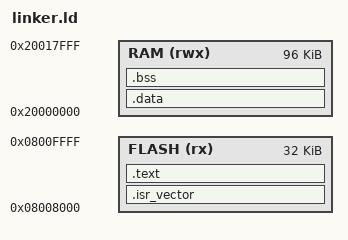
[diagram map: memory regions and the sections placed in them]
ENTRY(Reset_Handler)

MEMORY
{
    FLASH (rx) : ORIGIN = 0x08008000, LENGTH = 32K
    RAM (rwx)  : ORIGIN = 0x20000000, LENGTH = 96K
}

_estack = ORIGIN(RAM) + LENGTH(RAM);

SECTIONS
{
    .isr_vector :
    {
        . = ALIGN(128);
        KEEP(*(.isr_vector))
    } > FLASH

    .text :
    {
        *(.text*)
        *(.rodata*)
        . = ALIGN(4);
        _etext = .;
    } > FLASH

    .data : AT(_etext)
    {
        _sdata = .;
        *(.data*)
        _edata = .;
    } > RAM 

    _sidata = LOADADDR(.data);

    .bss :
    {
        _sbss = .;
        *(.bss*)
        *(COMMON)
        _ebss = .;
    } > RAM
}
